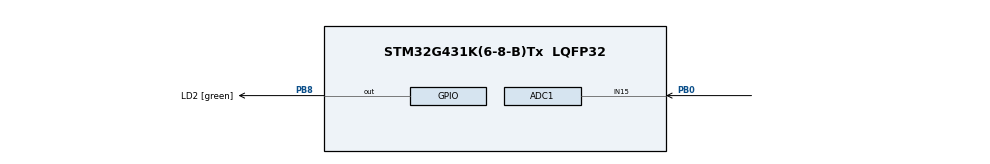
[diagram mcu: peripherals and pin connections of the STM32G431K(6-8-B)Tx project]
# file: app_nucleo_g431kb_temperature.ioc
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Mcu.Family=STM32G4
RCC.CortexFreq_Value=170000000
ADC1.OffsetNumber-7\#ChannelRegularConversion=ADC_OFFSET_NONE
VP_ADC1_TempSens_Input.Mode=IN-TempSens
ADC1.ContinuousConvMode=ENABLE
Dma.ADC1.0.Polarity=HAL_DMAMUX_REQ_GEN_RISING
ADC1.SamplingTime-6\#ChannelRegularConversion=ADC_SAMPLETIME_2CYCLES_5
PA14.GPIO_Label=T_SWCLK
ADC1.OffsetNumber-4\#ChannelRegularConversion=ADC_OFFSET_NONE
RCC.SYSCLKSource=RCC_SYSCLKSOURCE_PLLCLK
ProjectManager.StackSize=0x400
ADC1.Channel-5\#ChannelRegularConversion=ADC_CHANNEL_TEMPSENSOR_ADC1
ADC1.Channel-3\#ChannelRegularConversion=ADC_CHANNEL_TEMPSENSOR_ADC1
RCC.HCLKFreq_Value=170000000
RCC.APB2TimFreq_Value=170000000
Dma.ADC1.0.Direction=DMA_PERIPH_TO_MEMORY
ADC1.Channel-2\#ChannelRegularConversion=ADC_CHANNEL_TEMPSENSOR_ADC1
Dma.ADC1.0.MemDataAlignment=DMA_MDATAALIGN_HALFWORD
RCC.AHBFreq_Value=170000000
ADC1.Channel-0\#ChannelRegularConversion=ADC_CHANNEL_TEMPSENSOR_ADC1
RCC.HSE_VALUE=8000000
PB3.Mode=Trace_Asynchronous_SW
RCC.ADC12Freq_Value=170000000
ADC1.SamplingTime-4\#ChannelRegularConversion=ADC_SAMPLETIME_2CYCLES_5
ADC1.Channel-6\#ChannelRegularConversion=ADC_CHANNEL_TEMPSENSOR_ADC1
ADC1.Rank-2\#ChannelRegularConversion=3
PA14.Mode=Trace_Asynchronous_SW
Dma.ADC1.0.PeriphInc=DMA_PINC_DISABLE
VP_SYS_VS_DBSignals.Mode=DisableDeadBatterySignals
ADC1.SamplingTime-0\#ChannelRegularConversion=ADC_SAMPLETIME_2CYCLES_5
ADC1.OffsetNumber-5\#ChannelRegularConversion=ADC_OFFSET_NONE
Mcu.Package=LQFP32
PA2.GPIO_Label=USART2_TX [ST-LINKV3E_VCP_RX]
ADC1.OffsetNumber-1\#ChannelRegularConversion=ADC_OFFSET_NONE
PB8-BOOT0.GPIO_Label=LD2 [green]
RCC.APB1TimFreq_Value=170000000
Dma.Request0=ADC1
ADC1.Rank-6\#ChannelRegularConversion=7
Dma.ADC1.0.EventEnable=DISABLE
RCC.HSI48_VALUE=48000000
ADC1.Rank-4\#ChannelRegularConversion=5
PA3.Signal=USART2_RX
PB3.GPIO_Label=T_SWO
Dma.ADC1.0.Instance=DMA1_Channel1
ADC1.Rank-0\#ChannelRegularConversion=1
ADC1.Channel-4\#ChannelRegularConversion=ADC_CHANNEL_TEMPSENSOR_ADC1
Dma.ADC1.0.SyncRequestNumber=1
ADC1.OffsetNumber-0\#ChannelRegularConversion=ADC_OFFSET_NONE
ADC1.OffsetNumber-3\#ChannelRegularConversion=ADC_OFFSET_NONE
RCC.EXTERNAL_CLOCK_VALUE=12288000
ADC1.SamplingTime-2\#ChannelRegularConversion=ADC_SAMPLETIME_2CYCLES_5
ADC1.Channel-7\#ChannelRegularConversion=ADC_CHANNEL_TEMPSENSOR_ADC1
PA13.Signal=SYS_JTMS-SWDIO
Dma.ADC1.0.PeriphDataAlignment=DMA_PDATAALIGN_HALFWORD
ProjectManager.TargetToolchain=STM32CubeIDE
Dma.ADC1.0.Mode=DMA_CIRCULAR
Dma.ADC1.0.SignalID=NONE
Dma.ADC1.0.SyncSignalID=NONE
Dma.ADC1.0.Priority=DMA_PRIORITY_LOW
ADC1.Channel-1\#ChannelRegularConversion=ADC_CHANNEL_TEMPSENSOR_ADC1
RCC.USBFreq_Value=170000000
RCC.LSE_VALUE=32768
PB0.Mode=IN15-Single-Ended
PB8-BOOT0.Signal=GPIO_Output
board=NUCLEO-G431KB
RCC.VCOOutputFreq_Value=340000000
Dma.ADC1.0.SyncPolarity=HAL_DMAMUX_SYNC_NO_EVENT
RCC.APB2Freq_Value=170000000
ADC1.DMAContinuousRequests=ENABLE
ADC1.NbrOfConversion=8
PA13.Mode=Trace_Asynchronous_SW
ADC1.OffsetNumber-2\#ChannelRegularConversion=ADC_OFFSET_NONE
Mcu.Name=STM32G431K(6-8-B)Tx
PA13.GPIO_Label=T_SWDIO
PA2.Signal=USART2_TX
ADC1.OffsetNumber-6\#ChannelRegularConversion=ADC_OFFSET_NONE
PB3.Signal=SYS_JTDO-SWO
ADC1.SamplingTime-1\#ChannelRegularConversion=ADC_SAMPLETIME_2CYCLES_5
RCC.SYSCLKFreq_VALUE=170000000
ADC1.master=1
ADC1.Rank-3\#ChannelRegularConversion=4
ADC1.SamplingTime-3\#ChannelRegularConversion=ADC_SAMPLETIME_2CYCLES_5
ADC1.Rank-1\#ChannelRegularConversion=2
Dma.ADC1.0.RequestNumber=1
Dma.ADC1.0.SyncEnable=DISABLE
PA14.Signal=SYS_JTCK-SWCLK
Dma.ADC1.0.MemInc=DMA_MINC_ENABLE
ProjectManager.HeapSize=0x200
ADC1.SamplingTime-5\#ChannelRegularConversion=ADC_SAMPLETIME_2CYCLES_5
RCC.HSI_VALUE=16000000
ADC1.Rank-7\#ChannelRegularConversion=8
NVIC.PriorityGroup=NVIC_PRIORITYGROUP_4
ADC1.NbrOfConversionFlag=1
RCC.PLLM=RCC_PLLM_DIV4
RCC.PLLN=85
ADC1.SamplingTime-7\#ChannelRegularConversion=ADC_SAMPLETIME_2CYCLES_5
NVIC.DMA1_Channel1_IRQn=true\:0\:0\:false\:false\:true\:false\:true
RCC.APB1Freq_Value=170000000
PB0.Signal=ADC1_IN15
ADC1.Rank-5\#ChannelRegularConversion=6
PA3.GPIO_Label=USART2_RX [ST-LINKV3E_VCP_TX]

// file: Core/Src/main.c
/* USER CODE BEGIN Header */
/**
 ******************************************************************************
 * @file           : main.c
 * @brief          : Main program body
 ******************************************************************************
 * @attention
 *
 * <h2><center>&copy; Copyright (c) 2021 STMicroelectronics.
 * All rights reserved.</center></h2>
 *
 * This software component is licensed by ST under BSD 3-Clause license,
 * the "License"; You may not use this file except in compliance with the
 * License. You may obtain a copy of the License at:
 *                        opensource.org/licenses/BSD-3-Clause
 *
 ******************************************************************************
 */
/* USER CODE END Header */
#include "main.h"
#include "adc.h"
#include "dma.h"
#include "gpio.h"

/* USER CODE BEGIN PV */

/* Variables for ADC conversion data */
__IO uint16_t aADCxConvertedData[ADC_CONVERTED_DATA_BUFFER_SIZE]; /* ADC group regular conversion data */

__IO uint32_t DWT_lastValue;
__IO uint32_t DWT_delta;

/* USER CODE END PV */

void SystemClock_Config(void);

int main(void) {

	/* MCU Configuration--------------------------------------------------------*/

	/* Reset of all peripherals, Initializes the Flash interface and the Systick. */

	LL_APB2_GRP1_EnableClock(LL_APB2_GRP1_PERIPH_SYSCFG);
	LL_APB1_GRP1_EnableClock(LL_APB1_GRP1_PERIPH_PWR);

	NVIC_SetPriorityGrouping(NVIC_PRIORITYGROUP_4);

	/* System interrupt init*/

	/** Disable the internal Pull-Up in Dead Battery pins of UCPD peripheral
	 */
	LL_PWR_DisableUCPDDeadBattery();

	/* Configure the system clock */
	SystemClock_Config();

	/* Initialize all configured peripherals */
	MX_GPIO_Init();
	MX_DMA_Init();
	MX_ADC1_Init();
	/* USER CODE BEGIN 2 */
	/* Start ADC group regular conversion */
	/* Note: Hardware constraint (refer to description of the function          */
	/*       below):                                                            */
	/*       On this STM32 serie, setting of this feature is conditioned to     */
	/*       ADC state:                                                         */
	/*       ADC must be enabled without conversion on going on group regular,  */
	/*       without ADC disable command on going.                              */
	/* Note: In this example, all these checks are not necessary but are        */
	/*       implemented anyway to show the best practice usages                */
	/*       corresponding to reference manual procedure.                       */
	/*       Software can be optimized by removing some of these checks, if     */
	/*       they are not relevant considering previous settings and actions    */
	/*       in user application.                                               */
	if ((LL_ADC_IsEnabled(ADC1) == 1) && (LL_ADC_IsDisableOngoing(ADC1) == 0)
			&& (LL_ADC_REG_IsConversionOngoing(ADC1) == 0)) {
		LL_ADC_REG_StartConversion(ADC1);
	} else {
		/* Error: ADC conversion start could not be performed */
		LED_Blinking(LED_BLINK_ERROR);
	}

	/* USER CODE END 2 */

	/* Infinite loop */
	/* USER CODE BEGIN WHILE */
	while (1) {

		LED_On();
		// short sampling time sampling time
		LL_mDelay(3 * 1000);
		LL_ADC_REG_StopConversion(ADC1);
		LL_ADC_REG_StartConversion(ADC1);
		LL_ADC_SetChannelSamplingTime(ADC1, LL_ADC_CHANNEL_TEMPSENSOR_ADC1,
				LL_ADC_SAMPLINGTIME_2CYCLES_5);
		LL_ADC_REG_StartConversion(ADC1);

		LED_Off();
		// long sampling time sampling time
		LL_mDelay(3 * 1000);
		LL_ADC_REG_StopConversion(ADC1);
		LL_ADC_REG_StartConversion(ADC1);
		LL_ADC_SetChannelSamplingTime(ADC1, LL_ADC_CHANNEL_TEMPSENSOR_ADC1,
				LL_ADC_SAMPLINGTIME_640CYCLES_5);
		LL_ADC_REG_StartConversion(ADC1);
	}
	/* USER CODE END WHILE */
	/* USER CODE BEGIN 3 */
	// }
	/* USER CODE END 3 */
}

void SystemClock_Config(void) {
	LL_FLASH_SetLatency(LL_FLASH_LATENCY_4);
	while (LL_FLASH_GetLatency() != LL_FLASH_LATENCY_4) {
	}
	LL_PWR_EnableRange1BoostMode();
	LL_RCC_HSI_Enable();
	/* Wait till HSI is ready */
	while (LL_RCC_HSI_IsReady() != 1) {
	}

	LL_RCC_HSI_SetCalibTrimming(64);
	LL_RCC_PLL_ConfigDomain_SYS(LL_RCC_PLLSOURCE_HSI, LL_RCC_PLLM_DIV_4, 85,
	LL_RCC_PLLR_DIV_2);
	LL_RCC_PLL_EnableDomain_SYS();
	LL_RCC_PLL_Enable();
	/* Wait till PLL is ready */
	while (LL_RCC_PLL_IsReady() != 1) {
	}

	LL_RCC_SetSysClkSource(LL_RCC_SYS_CLKSOURCE_PLL);
	LL_RCC_SetAHBPrescaler(LL_RCC_SYSCLK_DIV_2);
	/* Wait till System clock is ready */
	while (LL_RCC_GetSysClkSource() != LL_RCC_SYS_CLKSOURCE_STATUS_PLL) {
	}

	/* Insure 1µs transition state at intermediate medium speed clock based on DWT */
	CoreDebug->DEMCR |= CoreDebug_DEMCR_TRCENA_Msk;
	DWT->CTRL |= DWT_CTRL_CYCCNTENA_Msk;
	DWT->CYCCNT = 0;
	while (DWT->CYCCNT < 100)
		;
	/* Set AHB prescaler*/
	LL_RCC_SetAHBPrescaler(LL_RCC_SYSCLK_DIV_1);
	LL_RCC_SetAPB1Prescaler(LL_RCC_APB1_DIV_1);
	LL_RCC_SetAPB2Prescaler(LL_RCC_APB2_DIV_1);

	LL_Init1msTick(170000000);

	LL_SetSystemCoreClock(170000000);
	LL_RCC_SetADCClockSource(LL_RCC_ADC12_CLKSOURCE_SYSCLK);
}

/* USER CODE BEGIN 4 */

/**
 * @brief  Turn-on LED2.
 * @param  None
 * @retval None
 */
void LED_On(void) {
	/* Turn LED2 on */
	LL_GPIO_SetOutputPin(LD2_GPIO_Port, LD2_Pin);
}

/**
 * @brief  Turn-off LED2.
 * @param  None
 * @retval None
 */
void LED_Off(void) {
	/* Turn LED2 off */
	LL_GPIO_ResetOutputPin(LD2_GPIO_Port, LD2_Pin);
}

/**
 * @brief  Set LED2 to Blinking mode for an infinite loop (toggle period based on value provided as input parameter).
 * @param  Period : Period of time (in ms) between each toggling of LED
 *   This parameter can be user defined values. Pre-defined values used in that example are :
 *     @arg LED_BLINK_FAST : Fast Blinking
 *     @arg LED_BLINK_SLOW : Slow Blinking
 *     @arg LED_BLINK_ERROR : Error specific Blinking
 * @retval None
 */
void LED_Blinking(uint32_t Period) {
	/* Turn LED2 on */
	LL_GPIO_SetOutputPin(LD2_GPIO_Port, LD2_Pin);

	/* Toggle IO in an infinite loop */
	while (1) {
		LL_GPIO_TogglePin(LD2_GPIO_Port, LD2_Pin);
		LL_mDelay(Period);
	}
}

/**
 * @brief  DMA transfer complete callback
 * @note   This function is executed when the transfer complete interrupt
 *         is generated
 * @retval None
 */
void AdcDmaTransferComplete_Callback() {

	// marker for tracking speed of conversion
	DWT_delta = DWT->CYCCNT - DWT_lastValue;
	DWT_lastValue = DWT->CYCCNT;
}

/**
 * @brief  DMA transfer error callback
 * @note   This function is executed when the transfer error interrupt
 *         is generated during DMA transfer
 * @retval None
 */
void AdcDmaTransferError_Callback() {
	/* Error detected during DMA transfer */
	LED_Blinking(LED_BLINK_ERROR);
}

/* USER CODE END 4 */

void Error_Handler(void) {
	__disable_irq();
	while (1) {
	}
}

/************************ (C) COPYRIGHT STMicroelectronics *****END OF FILE****/
